# RA6M2 register map
Vendor: Renesas Electronics Corporation; Series: RA6; File version: 1.1
CPU: CM4 r0p1, little endian, MPU, FPU, VTOR, 4 interrupt priority bits
Registers are 8-bit, read-write, reset 0x0 unless marked. A register's access mark holds for its fields unless they carry their own. Offsets are from the block's base; [hi:lo] are bit positions; {n}, {i} and the like mark numbered series; 'fields as' and 'values as' point back to an identical list.

## DMA — DMAC Module Activation
Base 0x40005200
0x00 DMAST — DMA Module Activation Register
  [0] DMST — DMAC Operation Enable
    0=DMAC activation is disabled; 1=DMAC activation is enabled

## DTC — Data Transfer Controller
Base 0x40005400
0x00 DTCCR reset 0x8 — DTC Control Register
  [4] RRS — DTC Transfer Information Read Skip Enable.
    0=Do not skip transfer information read; 1=Skip transfer information read when vector numbers match
0x04 DTCVBR 32-bit — DTC Vector Base Register
  [31:0] DTCVBR — DTC Vector Base Address.Note: A value cannot be set in the lower-order 10 bits. These bits are fixed to 0.
0x0C DTCST — DTC Module Start Register
  [0] DTCST — DTC Module Start
    0=DTC module stop; 1=DTC module start
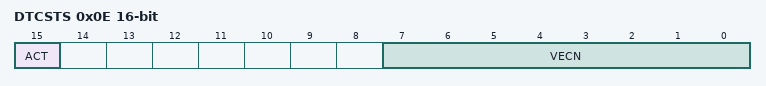
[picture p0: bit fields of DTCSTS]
0x0E DTCSTS 16-bit ro — DTC Status Register
  [15] ACT — DTC Active Flag
    0=DTC transfer operation is not in progress; 1=DTC transfer operation is in progress
  [7:0] VECN — DTC-Activating Vector Number MonitoringThese bits indicate the vector number for the activating source when DTC transfer is in progress.The value is only valid if DTC transfer is in progress (the value of the ACT flag is 1)

## MMF — Memory Mirror Function
Base 0x40001000
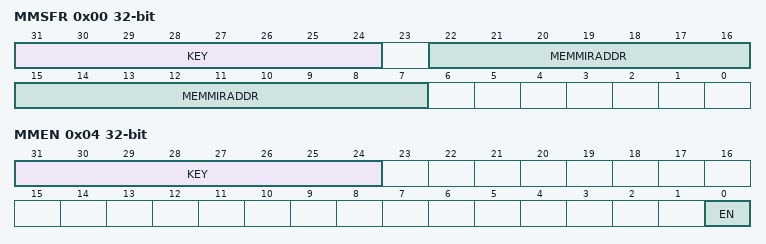
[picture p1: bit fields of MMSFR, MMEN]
0x00 MMSFR 32-bit — MemMirror Special Function Register
  [31:24] KEY wo — MMSFR Key Code
    219=Writing to the MEMMIRADDR bits are valid, when the KEY bits are written 0xDB; other=others (Writing to the MEMMIRADDR bits are invalid.)
  [22:7] MEMMIRADDR — Specifies the memory mirror address.NOTE: A value cannot be set in the low-order 7 bits. These bits are fixed to 0.
0x04 MMEN 32-bit — MemMirror Enable Register
  [31:24] KEY wo — MMEN Key Code
    219=Writing to the EN bit is valid, when the KEY bits are written 0xDB; other=others (Writing to the EN bit is invalid.)
  [0] EN — Memory Mirror Function Enable
    1=Memory Mirror Function is enabled; 0=Memory Mirror Function is disabled

## MMPU — Bus Master MPU
Base 0x40000000
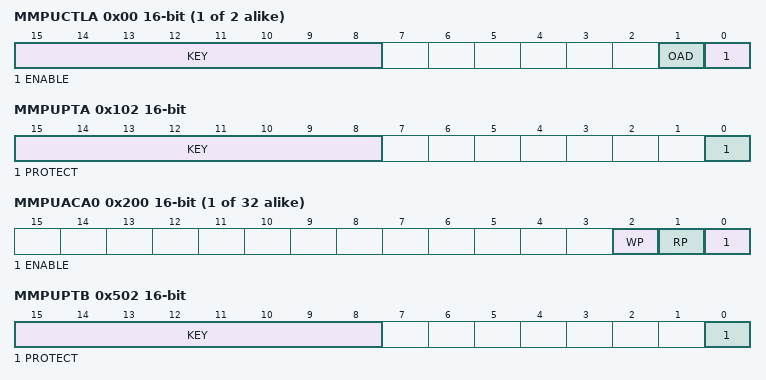
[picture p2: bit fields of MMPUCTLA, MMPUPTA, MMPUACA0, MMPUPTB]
0x00 MMPUCTL{x} (x=A,B; step 0x400) 16-bit — Bus Master MPU Control Register
  [15:8] KEY wo — Write Keyword The data written to these bits are not stored.
    165=Writing to the OAD and ENABLE bit is valid, when the KEY bits are written 0xA5; other=others (Writing to the OAD and ENABLE bit is invalid.)
  [1] OAD — Operation after detection
    0=Non-maskable interrupt; 1=Internal reset
  [0] ENABLE — Master Group enable
    0=Master Group is disabled. Permission of all regions.; 1=Master Group is enabled. Protection of all regions.
0x102 MMPUPTA 16-bit — Group A Protection of Register
  [15:8] KEY wo — Write Keyword The data written to these bits are not stored.
    165=Writing to the PROTECT bit is valid, when the KEY bits are written 0xA5; other=others (Writing to the PROTECT bit is invalid.)
  [0] PROTECT — Protection of register(MMPUSAn, MMPUEAn and MMPUACAn)
    0=All Bus Master MPU Group A register writing is possible; 1=All Bus Master MPU Group A register writing is protected. Read is possible.
{0x200+0x10*i} MMPUACA{i} (i=0..31) 16-bit — Group A Region {i} Access Control Register
  [2] WP — Write protection
    0=Write permission; 1=Write protection
  [1] RP — Read protection
    0=Read permission; 1=Read protection
  [0] ENABLE — Region enable
    0=Group m Region n unit is disabled; 1=Group m Region n unit is enabled
{0x204+0x10*i} MMPUSA{i} (i=0..31) 32-bit (reset mask 0x3) — Group A Region {i} Start Address Register
  [31:0] MMPUSA — Address where the region starts, for use in region determination.NOTE: The low-order 2 bits are fixed to 0.
{0x208+0x10*i} MMPUEA{i} (i=0..31) 32-bit reset 0x3 (reset mask 0x3) — Group A Region {i} End Address Register
  [31:0] MMPUEA — Region end address registerAddress where the region end, for use in region determination.NOTE: The low-order 2 bits are fixed to 1.
0x502 MMPUPTB 16-bit — Group B Protection of Register
  [15:8] KEY wo — Write Keyword The data written to these bits are not stored.
    values as MMPUPTA.KEY
  [0] PROTECT — Protection of register(MMPUSBn, MMPUEBn and MMPUACBn)
    0=All Bus Master MPU Group B register writing is possible; 1=All Bus Master MPU Group B register writing is protected. Read is possible.
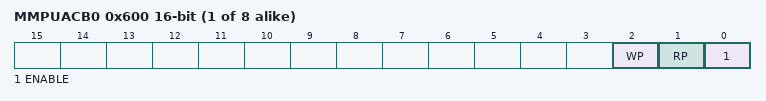
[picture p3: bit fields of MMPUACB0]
{0x600+0x10*i} MMPUACB{i} (i=0..7) 16-bit — Group B Region {i} Access Control Register
  fields as MMPUACA0
{0x604+0x10*i} MMPUSB{i} (i=0..7) 32-bit (reset mask 0x3) — Group B Region {i} Start Address Register
  [31:0] MMPUSB — Address where the region starts, for use in region determination.NOTE: The low-order 2 bits are fixed to 0.
{0x608+0x10*i} MMPUEB{i} (i=0..7) 32-bit reset 0x3 (reset mask 0x3) — Group B Region {i} End Address Register
  [31:0] MMPUEB — Region end address registerAddress where the region end, for use in region determination.NOTE: The low-order 2 bits are fixed to 1.
